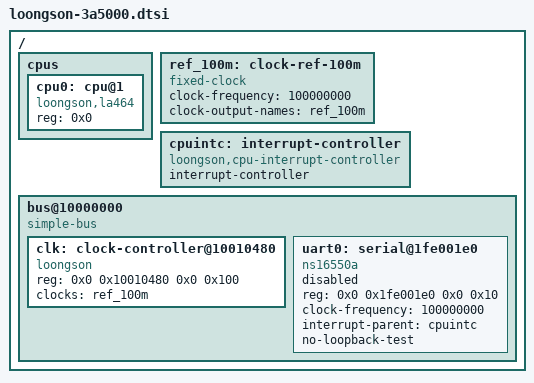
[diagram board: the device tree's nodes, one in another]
// SPDX-License-Identifier: GPL-2.0
/*
 * Copyright (C) 2023 Loongson Technology Corporation Limited
 */

 /dts-v1/;

 #include <dt-bindings/interrupt-controller/irq.h>
 #include <dt-bindings/clock/loongson,ls2k-clk.h>
 
 / {
	 #address-cells = <2>;
	 #size-cells = <2>;
 
	 cpus {
		 #address-cells = <1>;
		 #size-cells = <0>;
 
		 cpu0: cpu@1 {
			 compatible = "loongson,la464";
			 device_type = "cpu";
			 reg = <0x0>;
			//  clocks = <&clk LOONGSON2_NODE_CLK>;
		 };
 
		//  cpu1: cpu@2 {
		// 	 compatible = "loongson,la464";
		// 	 device_type = "cpu";
		// 	 reg = <0x1>;
		// 	 clocks = <&clk LOONGSON2_NODE_CLK>;
		//  };
	 };
 
	 ref_100m: clock-ref-100m {
		 compatible = "fixed-clock";
		 #clock-cells = <0>;
		 clock-frequency = <100000000>;
		 clock-output-names = "ref_100m";
	 };
 
	 cpuintc: interrupt-controller {
		 compatible = "loongson,cpu-interrupt-controller";
		 #interrupt-cells = <1>;
		 interrupt-controller;
	 };
 
	//  thermal-zones {
	// 	 cpu-thermal {
	// 		 polling-delay-passive = <1000>;
	// 		 polling-delay = <5000>;
	// 		 thermal-sensors = <&tsensor 0>;
 
	// 		 trips {
	// 			 cpu-alert {
	// 				 temperature = <40000>;
	// 				 hysteresis = <2000>;
	// 				 type = "active";
	// 			 };
 
	// 			 cpu-crit {
	// 				 temperature = <85000>;
	// 				 hysteresis = <5000>;
	// 				 type = "critical";
	// 			 };
	// 		 };
	// 	 };
	//  };
 
	 bus@10000000 {
		 compatible = "simple-bus";
		 ranges = <0x0 0x10000000 0x0 0x10000000 0x0 0x10000000>,
			  <0x0 0x02000000 0x0 0x02000000 0x0 0x02000000>,
			  <0x0 0x40000000 0x0 0x40000000 0x0 0x40000000>,
			  <0xfe 0x0 0xfe 0x0 0x0 0x40000000>;
		 #address-cells = <2>;
		 #size-cells = <2>;
 
		//  isa@18400000 {
		// 	 compatible = "isa";
		// 	 #size-cells = <1>;
		// 	 #address-cells = <2>;
		// 	 ranges = <1 0x0 0x0 0x18400000 0x4000>;
		//  };
 
		 clk: clock-controller@10010480 {
			 compatible = "loongson";
			 reg = <0x0 0x10010480 0x0 0x100>;
			 #clock-cells = <1>;
			 clocks = <&ref_100m>;
			 clock-names = "ref_100m";
		 };
 
		//  pmc: power-management@100d0000 {
		// 	 compatible = "loongson,ls2k2000-pmc", "loongson,ls2k0500-pmc", "syscon";
		// 	 reg = <0x0 0x100d0000 0x0 0x58>;
		// 	 interrupt-parent = <&eiointc>;
		// 	 interrupts = <47>;
		// 	 loongson,suspend-address = <0x0 0x1c000500>;
 
		// 	 syscon-reboot {
		// 		 compatible = "syscon-reboot";
		// 		 offset = <0x30>;
		// 		 mask = <0x1>;
		// 	 };
 
		// 	 syscon-poweroff {
		// 		 compatible = "syscon-poweroff";
		// 		 regmap = <&pmc>;
		// 		 offset = <0x14>;
		// 		 mask = <0x3c00>;
		// 		 value = <0x3c00>;
		// 	 };
		//  };
 
		//  tsensor: thermal-sensor@1fe01460 {
		// 	 compatible = "loongson";
		// 	 reg = <0x0 0x1fe01460 0x0 0x30>,
		// 	       <0x0 0x1fe0019c 0x0 0x4>;
		// 	 interrupt-parent = <&liointc>;
		// 	 interrupts = <7 IRQ_TYPE_LEVEL_HIGH>;
		// 	 #thermal-sensor-cells = <1>;
		//  };
 
		//  liointc: interrupt-controller@1fe01400 {
		// 	 compatible = "loongson,liointc-1.0";
		// 	 reg = <0x0 0x1fe01400 0x0 0x64>;
 
		// 	 interrupt-controller;
		// 	 #interrupt-cells = <2>;
		// 	 interrupt-parent = <&cpuintc>;
		// 	 interrupts = <2>;
		// 	 interrupt-names = "int0";
		// 	 loongson,parent_int_map = <0xffffffff>, /* int0 */
		// 				   <0x00000000>, /* int1 */
		// 				   <0x00000000>, /* int2 */
		// 				   <0x00000000>; /* int3 */
		//  };
 
		//  eiointc: interrupt-controller@1fe01600 {
		// 	 compatible = "loongson,ls2k2000-eiointc";
		// 	 reg = <0x0 0x1fe01600 0x0 0xea00>;
		// 	 interrupt-controller;
		// 	 #interrupt-cells = <1>;
		// 	 interrupt-parent = <&cpuintc>;
		// 	 interrupts = <3>;
		//  };
 
		//  pic: interrupt-controller@10000000 {
		// 	 compatible = "loongson,pch-pic-1.0";
		// 	 reg = <0x0 0x10000000 0x0 0x400>;
		// 	 interrupt-controller;
		// 	 #interrupt-cells = <2>;
		// 	 loongson,pic-base-vec = <0>;
		// 	 interrupt-parent = <&eiointc>;
		//  };
 
		//  msi: msi-controller@1fe01140 {
		// 	 compatible = "loongson,pch-msi-1.0";
		// 	 reg = <0x0 0x1fe01140 0x0 0x8>;
		// 	 interrupt-controller;
		// 	 #interrupt-cells = <1>;
		// 	 msi-controller;
		// 	 loongson,msi-base-vec = <64>;
		// 	 loongson,msi-num-vecs = <192>;
		// 	 interrupt-parent = <&eiointc>;
		//  };
 
		//  rtc0: rtc@100d0100 {
		// 	 compatible = "loongson,ls2k2000-rtc", "loongson,ls7a-rtc";
		// 	 reg = <0x0 0x100d0100 0x0 0x100>;
		// 	 interrupt-parent = <&pic>;
		// 	 interrupts = <52 IRQ_TYPE_LEVEL_HIGH>;
		// 	 status = "disabled";
		//  };
 
		 uart0: serial@1fe001e0 {
			 compatible = "ns16550a";
			 reg = <0x0 0x1fe001e0 0x0 0x10>;
			 clock-frequency = <100000000>;
			//  interrupt-parent = <&liointc>;
			 interrupt-parent = <&cpuintc>;
			//  interrupts = <10 IRQ_TYPE_LEVEL_HIGH>;
			 no-loopback-test;
			 status = "disabled";
		 };
 
	 };
 };
 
